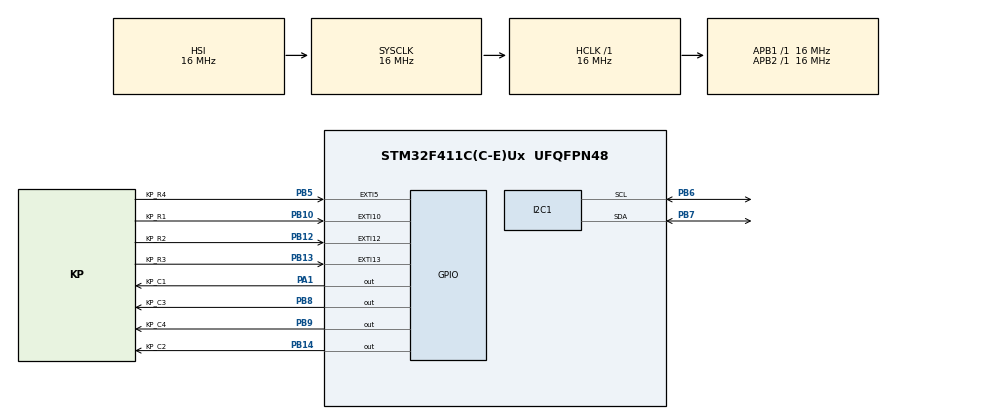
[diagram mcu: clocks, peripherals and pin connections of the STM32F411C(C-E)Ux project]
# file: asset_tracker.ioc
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ADC1.Channel-0\#ChannelRegularConversion=ADC_CHANNEL_VREFINT
ADC1.NbrOfConversionFlag=1
ADC1.Rank-0\#ChannelRegularConversion=1
ADC1.SamplingTime-0\#ChannelRegularConversion=ADC_SAMPLETIME_480CYCLES
ADC1.master=1
Mcu.Family=STM32F4
Mcu.Name=STM32F411C(C-E)Ux
Mcu.Package=UFQFPN48
NVIC.EXTI15_10_IRQn=true\:3\:0\:true\:false\:true\:true\:true\:true
NVIC.EXTI9_5_IRQn=true\:3\:0\:true\:false\:true\:true\:true\:true
NVIC.PriorityGroup=NVIC_PRIORITYGROUP_4
NVIC.RTC_WKUP_IRQn=true\:2\:0\:true\:false\:true\:true\:true\:true
NVIC.TIM5_IRQn=true\:2\:0\:true\:false\:true\:true\:true\:true
PA1.GPIO_Label=KP_C1
PA1.Signal=GPIO_Output
PA13.Mode=Serial_Wire
PA13.Signal=SYS_JTMS-SWDIO
PA14.Mode=Serial_Wire
PA14.Signal=SYS_JTCK-SWCLK
PB10.GPIO_Label=KP_R1
PB10.GPIO_ModeDefaultEXTI=GPIO_MODE_IT_FALLING
PB10.GPIO_PuPd=GPIO_PULLUP
PB10.Signal=GPXTI10
PB12.GPIO_Label=KP_R2
PB12.GPIO_ModeDefaultEXTI=GPIO_MODE_IT_FALLING
PB12.GPIO_PuPd=GPIO_PULLUP
PB12.Signal=GPXTI12
PB13.GPIO_Label=KP_R3
PB13.GPIO_ModeDefaultEXTI=GPIO_MODE_IT_FALLING
PB13.GPIO_PuPd=GPIO_PULLUP
PB13.Signal=GPXTI13
PB14.GPIO_Label=KP_C2
PB14.Signal=GPIO_Output
PB5.GPIO_Label=KP_R4
PB5.GPIO_ModeDefaultEXTI=GPIO_MODE_IT_FALLING
PB5.GPIO_PuPd=GPIO_PULLUP
PB5.Signal=GPXTI5
PB6.Mode=I2C
PB6.Signal=I2C1_SCL
PB7.Mode=I2C
PB7.Signal=I2C1_SDA
PB8.GPIO_Label=KP_C3
PB8.Signal=GPIO_Output
PB9.GPIO_Label=KP_C4
PB9.Signal=GPIO_Output
ProjectManager.HeapSize=0x200
ProjectManager.StackSize=0x1000
ProjectManager.TargetToolchain=CMake
RCC.AHBFreq_Value=16000000
RCC.APB1Freq_Value=16000000
RCC.APB2Freq_Value=16000000
RCC.CortexFreq_Value=16000000
RCC.HSE_VALUE=25000000
RCC.HSI_VALUE=16000000
RCC.LSE_VALUE=32768
RCC.SYSCLKFreq_VALUE=16000000
RCC.VCOOutputFreq_Value=192000000
RTC.SynchPrediv=249
RTC.WakeUpClock=RTC_WAKEUPCLOCK_CK_SPRE_16BITS
RTC.WakeUpCounter=9
VP_ADC1_Vref_Input.Mode=IN-Vrefint
VP_RTC_VS_RTC_Activate.Mode=RTC_Enabled
VP_RTC_VS_RTC_Calendar.Mode=RTC_Calendar
VP_RTC_VS_RTC_WakeUp_intern.Mode=WakeUp
VP_TIM5_VS_ClockSourceINT.Mode=Internal
board=custom

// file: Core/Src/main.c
/* USER CODE BEGIN Header */
/**
  ******************************************************************************
  * @file           : main.c
  * @brief          : Main program body
  ******************************************************************************
  * @attention
  *
  * Copyright (c) 2026 STMicroelectronics.
  * All rights reserved.
  *
  * This software is licensed under terms that can be found in the LICENSE file
  * in the root directory of this software component.
  * If no LICENSE file comes with this software, it is provided AS-IS.
  *
  ******************************************************************************
  */
/* USER CODE END Header */
#include "main.h"
#include "adc.h"
#include "i2c.h"
#include "rtc.h"
#include "tim.h"
#include "gpio.h"

/* USER CODE BEGIN Includes */
#include "app_main.h"

/* USER CODE END Includes */

void SystemClock_Config(void);

int main(void)
{

  /* MCU Configuration--------------------------------------------------------*/

  /* Reset of all peripherals, Initializes the Flash interface and the Systick. */
  HAL_Init();

  /* Configure the system clock */
  SystemClock_Config();

  /* Initialize all configured peripherals */
  MX_GPIO_Init();
  MX_ADC1_Init();
  MX_I2C1_Init();
  MX_RTC_Init();
  MX_TIM5_Init();
  /* USER CODE BEGIN 2 */
  app_init();
  app_run();   /* never returns */

  /* USER CODE END 2 */

  /* Infinite loop */
  while (1)
  {

  }
}

void SystemClock_Config(void)
{
  RCC_OscInitTypeDef RCC_OscInitStruct = {0};
  RCC_ClkInitTypeDef RCC_ClkInitStruct = {0};

  /** Configure the main internal regulator output voltage
  */
  __HAL_RCC_PWR_CLK_ENABLE();
  __HAL_PWR_VOLTAGESCALING_CONFIG(PWR_REGULATOR_VOLTAGE_SCALE1);

  /** Initializes the RCC Oscillators according to the specified parameters
  * in the RCC_OscInitTypeDef structure.
  */
  RCC_OscInitStruct.OscillatorType = RCC_OSCILLATORTYPE_HSI|RCC_OSCILLATORTYPE_LSI;
  RCC_OscInitStruct.HSIState = RCC_HSI_ON;
  RCC_OscInitStruct.HSICalibrationValue = RCC_HSICALIBRATION_DEFAULT;
  RCC_OscInitStruct.LSIState = RCC_LSI_ON;
  RCC_OscInitStruct.PLL.PLLState = RCC_PLL_NONE;
  if (HAL_RCC_OscConfig(&RCC_OscInitStruct) != HAL_OK)
  {
    Error_Handler();
  }

  /** Initializes the CPU, AHB and APB buses clocks
  */
  RCC_ClkInitStruct.ClockType = RCC_CLOCKTYPE_HCLK|RCC_CLOCKTYPE_SYSCLK
                              |RCC_CLOCKTYPE_PCLK1|RCC_CLOCKTYPE_PCLK2;
  RCC_ClkInitStruct.SYSCLKSource = RCC_SYSCLKSOURCE_HSI;
  RCC_ClkInitStruct.AHBCLKDivider = RCC_SYSCLK_DIV1;
  RCC_ClkInitStruct.APB1CLKDivider = RCC_HCLK_DIV1;
  RCC_ClkInitStruct.APB2CLKDivider = RCC_HCLK_DIV1;

  if (HAL_RCC_ClockConfig(&RCC_ClkInitStruct, FLASH_LATENCY_0) != HAL_OK)
  {
    Error_Handler();
  }
}

void Error_Handler(void)
{
  __disable_irq();
  while (1)
  {
  }
}
